# R7FA6M3AH register map
Vendor: Renesas; Series: RA6; File version: 1.2
CPU: CM4 r0p1, little endian, MPU, FPU, VTOR, 4 interrupt priority bits
Registers are 32-bit, read-write, reset 0x0 unless marked. A register's access mark holds for its fields unless they carry their own. Offsets are from the block's base; [hi:lo] are bit positions; {n}, {i} and the like mark numbered series; 'fields as' and 'values as' point back to an identical list.

## GLCDC — Graphics LCD Controller
Base 0x400E0000
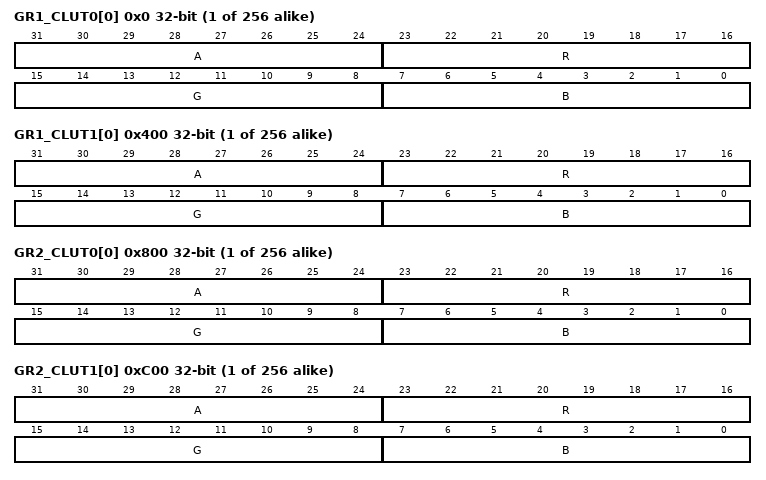
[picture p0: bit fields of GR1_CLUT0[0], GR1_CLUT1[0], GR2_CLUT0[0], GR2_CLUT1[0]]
{0x0+4i} GR1_CLUT0[{i}] (i=0..255) reset not defined — Color Palette 0 Plane for Graphics 1 Plane
  [31:24] A — Alpha Blending Value of Color Palette n Plane for Graphics m Plane
  [23:16] R — R Value of Color Palette n Plane for Graphics m Plane
  [15:8] G — G Value of Color Palette n Plane for Graphics m Plane
  [7:0] B — B Value of Color Palette n Plane for Graphics m Plane
{0x400+4i} GR1_CLUT1[{i}] (i=0..255) reset not defined — Color Palette 1 Plane for Graphics 1 Plane
  fields as GR1_CLUT0[0]
{0x800+4i} GR2_CLUT0[{i}] (i=0..255) reset not defined — Color Palette 0 Plane for Graphics 2 Plane
  fields as GR1_CLUT0[0]
{0xC00+4i} GR2_CLUT1[{i}] (i=0..255) reset not defined — Color Palette 1 Plane for Graphics 2 Plane
  fields as GR1_CLUT0[0]
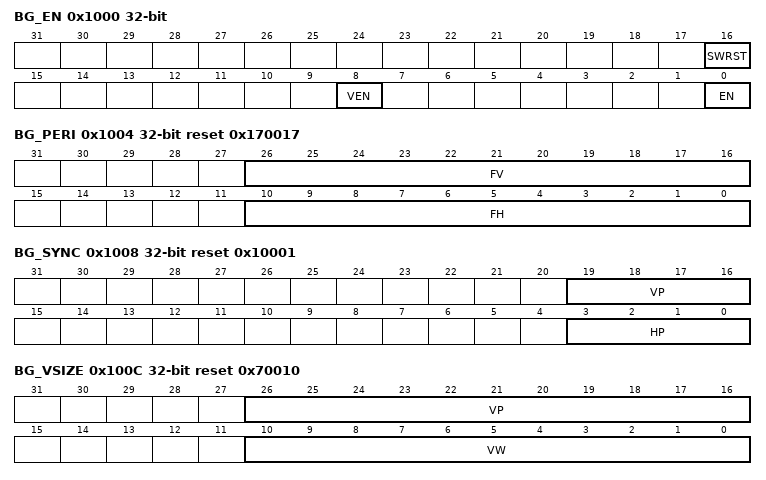
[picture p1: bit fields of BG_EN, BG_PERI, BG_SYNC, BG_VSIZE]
0x1000 BG_EN — Background Plane Setting Operation Control Register
  [16] SWRST — Entire module SW reset control
  [8] VEN write-1-sets read-modifies — Control of LCDC internal register value reflection to internal operations
  [0] EN — Background plane generation module operation enable
0x1004 BG_PERI reset 0x170017 — Background Plane Setting Free,Running Period Register
  [26:16] FV range 0x013..0x3FF — Background plane vertical synchronization signal period on the basis of line.
  [10:0] FH range 0x017..0x3FF — Background plane horizontal synchronization signal period on the basis of pixel clock (PXCLK).
0x1008 BG_SYNC reset 0x10001 — Background Plane Setting Synchronization Position Register
  [19:16] VP — Background plane vertical synchronization signal assertion position on the basis of line.
  [3:0] HP — Background plane horizontal synchronization signal assertion position on the basis of pixel clock (PXCLK).
0x100C BG_VSIZE reset 0x70010 — Background Plane Setting Full Image Vertical Size Register
  [26:16] VP range 0x0003..0x3EF — Background plane vertical valid pixel start position on the basis of line
  [10:0] VW range 0x0010..0x03FC — Background plane vertical valid pixel width on the basis of line
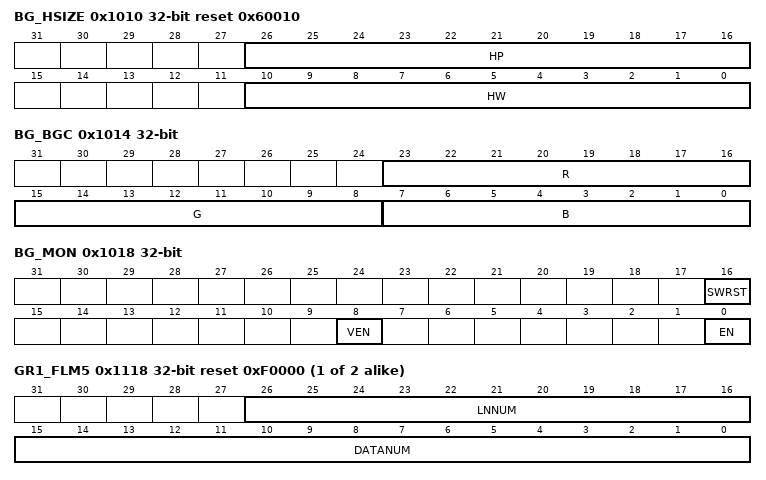
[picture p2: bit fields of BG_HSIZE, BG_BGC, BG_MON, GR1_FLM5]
0x1010 BG_HSIZE reset 0x60010 — Background Plane Setting Full Image Horizontal Size Register
  [26:16] HP range 0x006..0x3EE — Background plane horizontal valid pixel start position on the basis of pixel clock (PXCLK).
  [10:0] HW range 0x010..0x3F8 — Background plane horizontall valid pixel width on the basis of pixel clock (PXCLK)Note: When serial RGB is selected as the output format for the output control block, add two to the horizontal enable signal width and set the resulting value to this field.
0x1014 BG_BGC — Background Plane Setting Background Color Register
  [23:16] R — R value for background plane valid pixel area.Unsigned; 8-bit integer.
  [15:8] G — G value for background plane valid pixel areaUnsigned; 8-bit integer
  [7:0] B — B value for background plane valid pixel areaUnsigned; 8-bit integer
0x1018 BG_MON ro — Background Plane Setting Status Monitor Register
  [16] SWRST — Entire module SW reset state monitor.
  [8] VEN — Entire module internal operation reflection control signal monitor.The signal state for controlling reflection of the register values to the internal operations upon assertion of the vertical synchronization signal.
  [0] EN — Background plane generation module operation state monitor.
{0x1000+0x100*i} GR{i}_VEN (i=1..2) — Graphics {i} Register Update Control Register
  [0] PVEN write-0-clears read-modifies — Control of graphics n module register value reflection to internal operations.Reflection of the register values to the internal operation at the assertion of the vertical synchronization signal (VS).
{0x1004+0x100*i} GR{i}_FLMRD (i=1..2) — Graphics {i} Frame Buffer Read Control Register
  [0] RENB — Graphics data (frame buffer data) read enable.
{0x1008+0x100*i} GR{i}_FLM1 (i=1..2) reset 0x3 — Graphics {i} Frame Buffer Control Register 1
  [1:0] BSTMD — Burst transfer control for graphics data (frame buffer data)access
{0x100C+0x100*i} GR{i}_FLM2 (i=1..2) — Graphics {i} Frame Buffer Control Register 2
  [31:0] BASE — Base address for accessing graphics data (frame buffer data)Set the head address in the frame buffer where graphics data is to be stored. GRn_FLM2.BASE[5:0] should be fixed to 0 during 64-byte burst transfer.
{0x1010+0x100*i} GR{i}_FLM3 (i=1..2) — Graphics {i} Frame Buffer Control Register 3
  [31:16] LNOFF — Macro line offset address for accessing graphics data(frame buffer data)Signed; 16-bit integer
{0x1018+0x100*i} GR{i}_FLM5 (i=1..2) reset 0xF0000 — Graphics {i} Frame Buffer Control Register 5
  [26:16] LNNUM range 0x00F..0x3FF — Number of lines per frame for accessing graphics data (frame buffer data).
  [15:0] DATANUM — Number of data transfer times per line for accessing graphics data (frame buffer data), where one transfer is defined as 16-beat burst access (64-byte boundary)
{0x101C+0x100*i} GR{i}_FLM6 (i=1..2) — Graphics {i} Frame Buffer Control Register 6
  [30:28] FORMAT — Data format for accessing graphics data (frame buffer data).
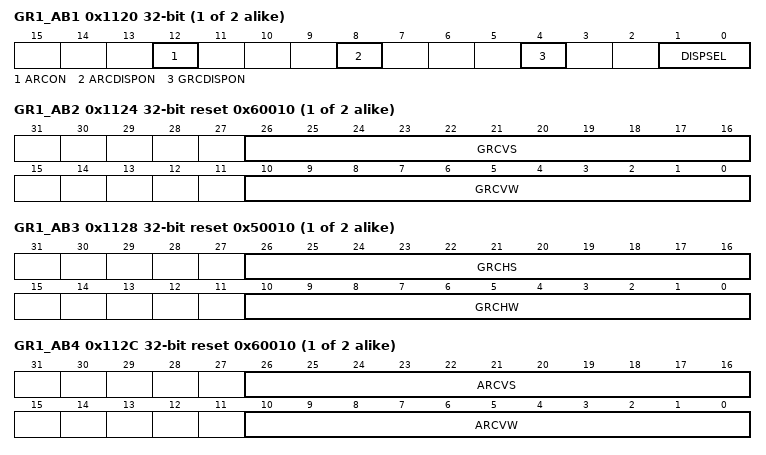
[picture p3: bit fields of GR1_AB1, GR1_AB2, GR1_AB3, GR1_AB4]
{0x1020+0x100*i} GR{i}_AB1 (i=1..2) — Graphics {i} Alpha Blending Control Register 1
  [12] ARCON — Rectangular area alpha blending control.
  [8] ARCDISPON — Image area border display control for rectangular area alpha blending.
  [4] GRCDISPON — Graphics image area border display control.
  [1:0] DISPSEL — Graphics display plane control.
{0x1024+0x100*i} GR{i}_AB2 (i=1..2) reset 0x60010 — Graphics {i} Alpha Blending Control Register 2
  [26:16] GRCVS range 0x002..0x3EE — Vertical start position of graphics image area.
  [10:0] GRCVW range 0x010..0x3FC — Vertical width of graphics image area.
{0x1028+0x100*i} GR{i}_AB3 (i=1..2) reset 0x50010 — Graphics {i} Alpha Blending Control Register 3
  [26:16] GRCHS range 0x005..0x3ED — Horizontal start position of graphics image area.
  [10:0] GRCHW range 0x010..0x3F0 — Horizontal width of graphics image area.
{0x102C+0x100*i} GR{i}_AB4 (i=1..2) reset 0x60010 — Graphics {i} Alpha Blending Control Register 4
  [26:16] ARCVS range 0x002..0x3EE — Vertical start position of rectangular area alpha blending image area
  [10:0] ARCVW range 0x001..0x3FC — Vertical width of rectangular area alpha blending image area.
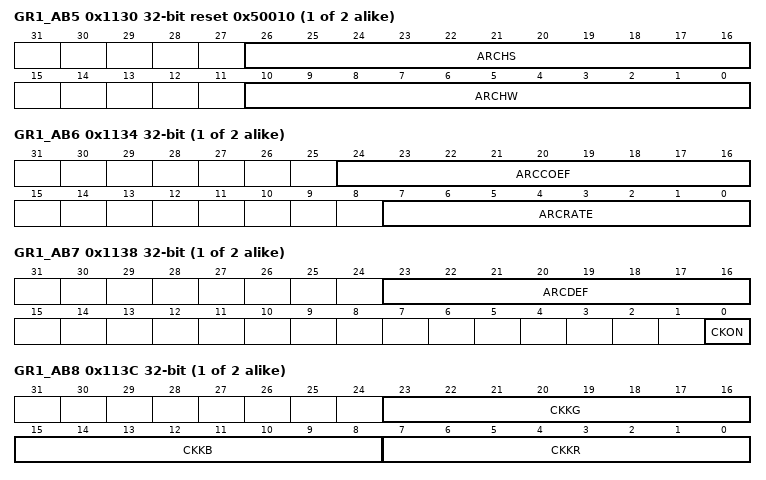
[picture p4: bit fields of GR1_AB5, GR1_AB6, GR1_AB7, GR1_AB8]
{0x1030+0x100*i} GR{i}_AB5 (i=1..2) reset 0x50010 — Graphics {i} Alpha Blending Control Register 5
  [26:16] ARCHS range 0x005..0x3ED — Horizontal start position of rectangular area alpha blending image area.
  [10:0] ARCHW range 0x001..0x3F8 — Horizontal width of rectangular area alpha blending image area.
{0x1034+0x100*i} GR{i}_AB6 (i=1..2) — Graphics {i} Alpha Blending Control Register 6
  [24:16] ARCCOEF — Alpha coefficient for alpha blending in rectangular area (-255 to 255).[8]: Sign (0: addition, 1: subtraction)[7:0]: Variation (absolute value)
  [7:0] ARCRATE — Frame rate for alpha blending in rectangular area.
{0x1038+0x100*i} GR{i}_AB7 (i=1..2) — Graphics {i} Alpha Blending Control Register 7
  [23:16] ARCDEF — Initial alpha value for alpha blending in rectangular area.
  [0] CKON — RGB,index chroma,key processing control.
{0x103C+0x100*i} GR{i}_AB8 (i=1..2) — Graphics {i} Alpha Blending Control Register 8
  [23:16] CKKG — G signal for RGB,index chroma,key processingUnsigned; 8 bits.
  [15:8] CKKB — B signal for RGB,index chroma,key processingUnsigned; 8 bits.
  [7:0] CKKR — R signal for RGB,index chroma,key processingUnsigned; 8 bits.
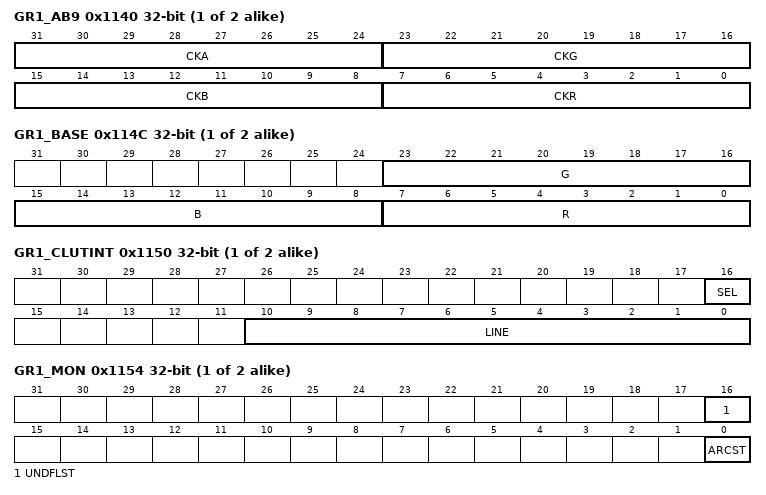
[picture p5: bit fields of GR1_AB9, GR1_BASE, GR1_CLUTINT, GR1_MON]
{0x1040+0x100*i} GR{i}_AB9 (i=1..2) — Graphics {i} Alpha Blending Control Register 9
  [31:24] CKA — A value after RGB,index chroma,key processing replacement.
  [23:16] CKG — G value after RGB,index chroma,key processing replacementUnsigned; 8 bits.
  [15:8] CKB — B value after RGB,index chroma,key processing replacementUnsigned; 8 bits.
  [7:0] CKR — R value after RGB,index chroma,key processing replacementUnsigned; 8 bits.
{0x104C+0x100*i} GR{i}_BASE (i=1..2) — Graphics {i} Background Color Control Register
  [23:16] G — Background color G valueUnsigned; 8 bits
  [15:8] B — Background color B valueUnsigned; 8 bits
  [7:0] R — Background color R valueUnsigned; 8 bits
{0x1050+0x100*i} GR{i}_CLUTINT (i=1..2) — Graphics {i} CLUT Table Interrupt Control Register
  [16] SEL — CLUT table control
  [10:0] LINE range 0x000..0x400 — Number of detection lines
{0x1054+0x100*i} GR{i}_MON (i=1..2) ro — Graphics {i} Status Monitor Register
  [16] UNDFLST — Status monitor for underflow
  [0] ARCST — Status monitor for alpha blending in rectangular area
0x1300 GAM{x}_LATCH (x=G,B,R; step 0x40) — Gamma {x} Register Update Control Register
  [0] VEN write-0-clears read-modifies — Control of gamma correction x module register value reflection to internal operations.The register values to be reflected to the internal operations at the assertion of the vertical synchronization signal (VS).
0x1304 GAM_SW — Gamma Correction Block Function Switch Register
  [0] GAMON — Gamma correction on/off control
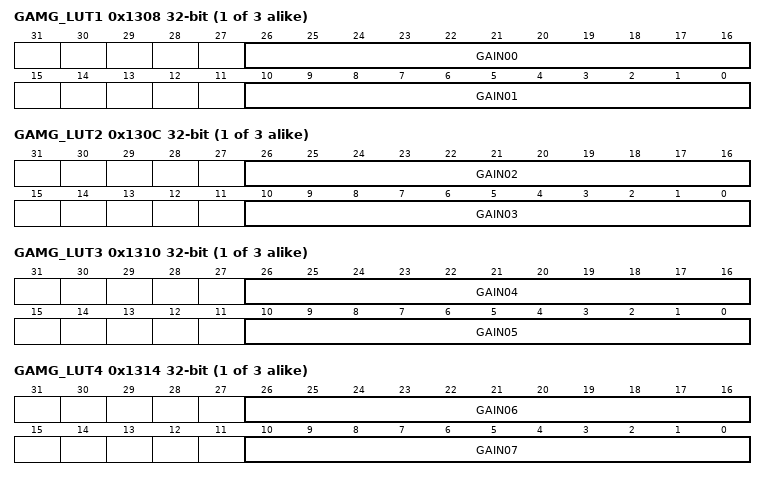
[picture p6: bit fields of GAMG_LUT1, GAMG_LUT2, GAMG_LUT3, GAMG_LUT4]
0x1308 GAM{x}_LUT1 (x=G,B,R; step 0x40) — Gamma {x} Correction Block Table Setting Register 1
  [26:16] GAIN00 — Gain value of area 0.Unsigned 11-bit fixed point.
  [10:0] GAIN01 — Gain value of area 1Unsigned 11-bit fixed point
0x130C GAM{x}_LUT2 (x=G,B,R; step 0x40) — Gamma {x} Correction Block Table Setting Register 2
  [26:16] GAIN02 — Gain value of area 2Unsigned 11-bit fixed point
  [10:0] GAIN03 — Gain value of area 3Unsigned 11-bit fixed point
0x1310 GAM{x}_LUT3 (x=G,B,R; step 0x40) — Gamma {x} Correction Block Table Setting Register 3
  [26:16] GAIN04 — Gain value of area 4Unsigned 11-bit fixed point
  [10:0] GAIN05 — Gain value of area 5Unsigned 11-bit fixed point
0x1314 GAM{x}_LUT4 (x=G,B,R; step 0x40) — Gamma {x} Correction Block Table Setting Register 4
  [26:16] GAIN06 — Gain value of area 6Unsigned 11-bit fixed point
  [10:0] GAIN07 — Gain value of area 7Unsigned 11-bit fixed point
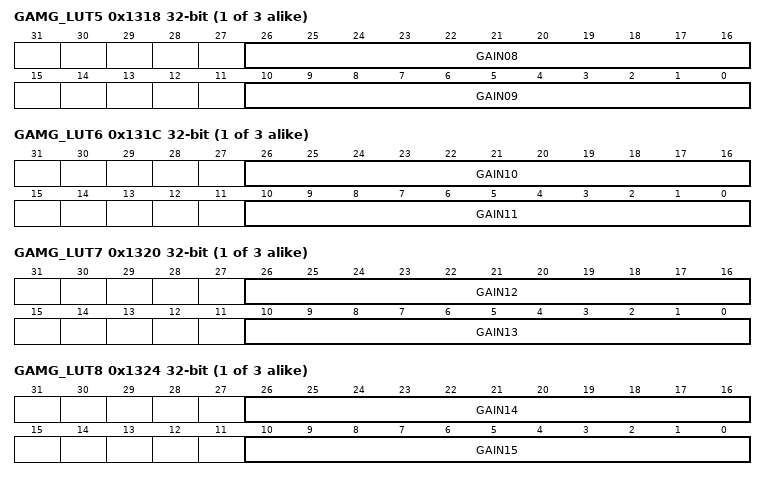
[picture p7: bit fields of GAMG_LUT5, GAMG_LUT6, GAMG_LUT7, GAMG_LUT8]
0x1318 GAM{x}_LUT5 (x=G,B,R; step 0x40) — Gamma {x} Correction Block Table Setting Register 5
  [26:16] GAIN08 — Gain value of area 8Unsigned 11-bit fixed point
  [10:0] GAIN09 — Gain value of area 9Unsigned 11-bit fixed point
0x131C GAM{x}_LUT6 (x=G,B,R; step 0x40) — Gamma {x} Correction Block Table Setting Register 6
  [26:16] GAIN10 — Gain value of area 10Unsigned 11-bit fixed point
  [10:0] GAIN11 — Gain value of area 11Unsigned 11-bit fixed point
0x1320 GAM{x}_LUT7 (x=G,B,R; step 0x40) — Gamma {x} Correction Block Table Setting Register 7
  [26:16] GAIN12 — Gain value of area 12Unsigned 11-bit fixed point
  [10:0] GAIN13 — Gain value of area 13Unsigned 11-bit fixed point
0x1324 GAM{x}_LUT8 (x=G,B,R; step 0x40) — Gamma {x} Correction Block Table Setting Register 8
  [26:16] GAIN14 — Gain value of area 14Unsigned 11-bit fixed point
  [10:0] GAIN15 — Gain value of area 15Unsigned 11-bit fixed point
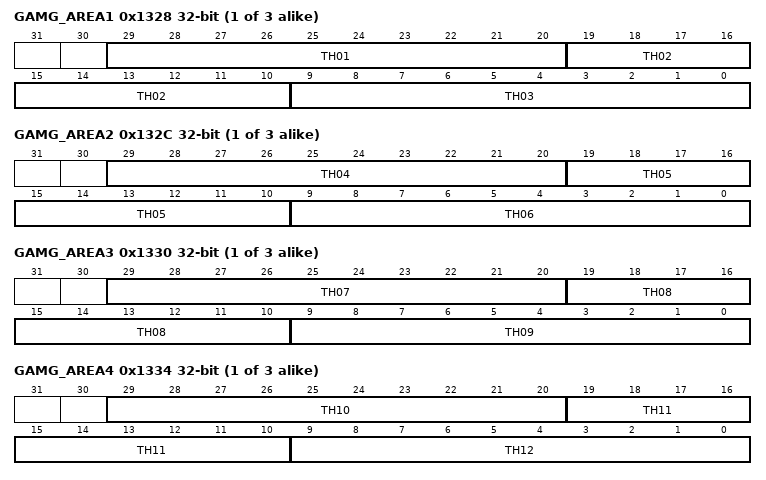
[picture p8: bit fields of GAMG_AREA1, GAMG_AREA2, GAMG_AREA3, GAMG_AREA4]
0x1328 GAM{x}_AREA1 (x=G,B,R; step 0x40) — Gamma {x} Correction Block Area Setting Register 1
  [29:20] TH01 — Start threshold of area 1Unsigned 10-bit integer
  [19:10] TH02 — Start threshold of area 2Unsigned 10-bit integer
  [9:0] TH03 — Start threshold of area 3Unsigned 10-bit integer
0x132C GAM{x}_AREA2 (x=G,B,R; step 0x40) — Gamma {x} Correction Block Area Setting Register 2
  [29:20] TH04 — Start threshold of area 4Unsigned 10-bit integer
  [19:10] TH05 — Start threshold of area 5Unsigned 10-bit integer
  [9:0] TH06 — Start threshold of area 6Unsigned 10-bit integer
0x1330 GAM{x}_AREA3 (x=G,B,R; step 0x40) — Gamma {x} Correction Block Area Setting Register 3
  [29:20] TH07 — Start threshold of area 7Unsigned 10-bit integer
  [19:10] TH08 — Start threshold of area 8Unsigned 10-bit integer
  [9:0] TH09 — Start threshold of area 9Unsigned 10-bit integer
0x1334 GAM{x}_AREA4 (x=G,B,R; step 0x40) — Gamma {x} Correction Block Area Setting Register 4
  [29:20] TH10 — Start threshold of area 10Unsigned 10-bit integer
  [19:10] TH11 — Start threshold of area 11Unsigned 10-bit integer
  [9:0] TH12 — Start threshold of area 12Unsigned 10-bit integer
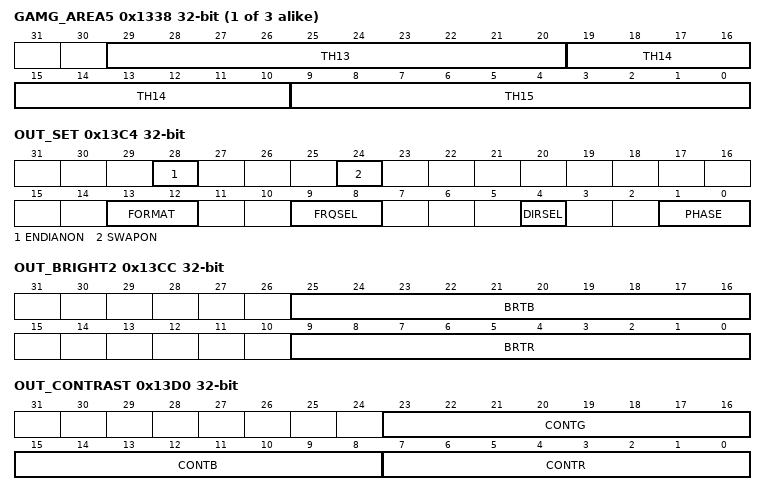
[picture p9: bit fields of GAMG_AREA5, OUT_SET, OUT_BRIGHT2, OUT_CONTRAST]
0x1338 GAM{x}_AREA5 (x=G,B,R; step 0x40) — Gamma {x} Correction Block Area Setting Register 5
  [29:20] TH13 — Start threshold of area 13Unsigned 10-bit integer
  [19:10] TH14 — Start threshold of area 14Unsigned 10-bit integer
  [9:0] TH15 — Start threshold of area 15Unsigned 10-bit integer
0x13C0 OUT_VLATCH — Output Control Block Register Update Control Register
  [0] VEN write-0-clears read-modifies — Control of output control module register value reflection to internal operations.The register values to be reflected to the internal operations at the assertion of the vertical synchronization signal (VS).
0x13C4 OUT_SET — Output Control Block Output Interface Register
  [28] ENDIANON — Bit endian change control
  [24] SWAPON — Pixel order control
  [13:12] FORMAT — Output format select
  [9:8] FRQSEL — Clock frequency division control
  [4] DIRSEL — Invalid data position control in serial RGB format
  [1:0] PHASE — Data delay in serial RGB format (based on OUTCLK)
0x13C8 OUT_BRIGHT1 — Output Control Block Brightness Correction Register 1
  [9:0] BRTG — Brightness (DC) adjustment of G signalUnsigned; 10 bits; +512 with offset; integer
0x13CC OUT_BRIGHT2 — Output Control Block Brightness Correction Register 2
  [25:16] BRTB — Brightness (DC) adjustment of B signalUnsigned; 10 bits; +512 with offset; integer
  [9:0] BRTR — Brightness (DC) adjustment of R signalUnsigned; 10 bits; +512 with offset; integer
0x13D0 OUT_CONTRAST — Output Control Block Contrast Correction Register
  [23:16] CONTG — Contrast (GAIN) adjustment of G signalUnsigned; 8 bits fixed point.
  [15:8] CONTB — Contrast (GAIN) adjustment of B signalUnsigned; 8 bits fixed point
  [7:0] CONTR — Contrast (GAIN) adjustment of R signalUnsigned; 8 bits fixed point
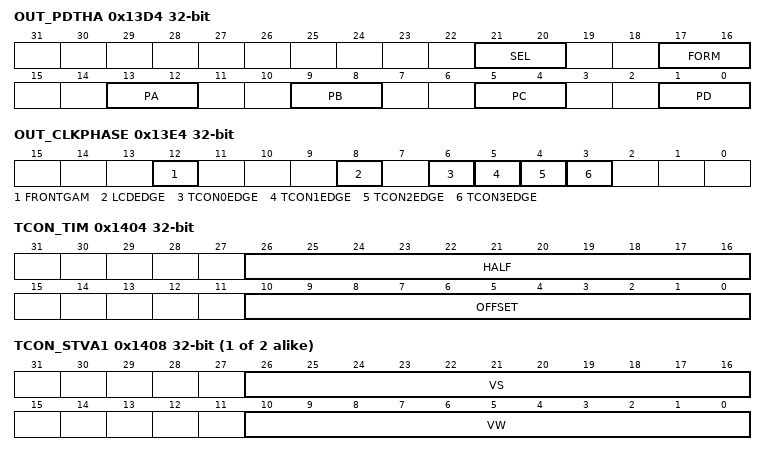
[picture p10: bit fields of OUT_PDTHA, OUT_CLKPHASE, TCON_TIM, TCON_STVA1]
0x13D4 OUT_PDTHA — Output Control Block Panel Dither Correction Register
  [21:20] SEL — Operation mode
  [17:16] FORM — Output format select
  [13:12] PA — Pattern value (A) of 2 x 2 pattern ditherUnsigned 2-bit integer
  [9:8] PB — Pattern value (B) of 2 x 2 pattern ditherUnsigned 2-bit integer
  [5:4] PC — Pattern value (C) of 2 x 2 pattern ditherUnsigned 2-bit integer
  [1:0] PD — Pattern value (D) of 2 x 2 pattern ditherUnsigned 2-bit integer
0x13E4 OUT_CLKPHASE — Output Control Block Output Phase Control Register
  [12] FRONTGAM — Correction control
  [8] LCDEDGE — LCD_DATA Output Phase Control
  [6-n] TCON{n}EDGE (n=0..3) — LCD_TCON{n} Output Phase Control
0x1404 TCON_TIM — TCON Reference Timing Setting Register
  [26:16] HALF range 0x000..0x3FF — Vertical synchronization signal generation change timing Sets the delay from the assertion of the internal horizontal synchronization signal in terms of pixels.
  [10:0] OFFSET range 0x000..0x3FF — Horizontal synchronization signal generation reference timingSets the offset from the assertion of the internal horizontal synchronization signal in terms of pixels.
0x1408 TCON_STV{x}1 (x=A,B; step 0x8) — TCON Vertical Timing Setting Register {x}1
  [26:16] VS range 0x000..0x7FF — STVx1 first change timing
  [10:0] VW range 0x000..0x7FF — STVx1 second change timingSets the signal assertion width.
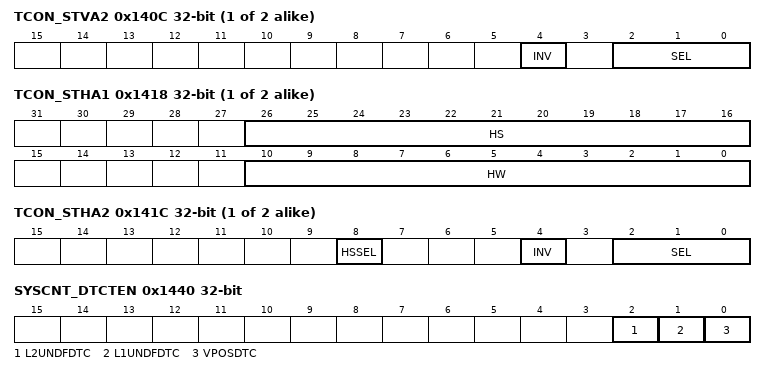
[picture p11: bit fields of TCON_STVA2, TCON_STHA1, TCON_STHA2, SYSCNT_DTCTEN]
0x140C TCON_STV{x}2 (x=A,B; step 0x8) — TCON Vertical Timing Setting Register {x}2
  [4] INV — STVx signal polarity inversion control
  [2:0] SEL — Output signal select control for VSOUT (controlled by TCON_STVA2 register)/VEOUT (controlled by the TCON_STVB2 register) pin
0x1418 TCON_STH{x}1 (x=A,B; step 0x8) — TCON Horizontal Timing Setting Register STH{x}1
  [26:16] HS range 0x000..0x3FF — STHx1 first change timing
  [10:0] HW range 0x000..0x3FF — STHx1 second change timing.Sets the signal assertion width.
0x141C TCON_STH{x}2 (x=A,B; step 0x8) — TCON Horizontal Timing Setting Register STH{x}2
  [8] HSSEL — STHx signal generation reference timing control.
  [4] INV — STVx signal polarity inversion control.
  [2:0] SEL — Output signal select control for LCD_TCON2 (controlled by TCON_STHA2 register)/LCD_TCON3 (controlled by the TCON_STHB2 register) pin.
0x1428 TCON_DE — TCON Data Enable Polarity Setting Register
  [0] INV — DE signal polarity inversion control.
0x1440 SYSCNT_DTCTEN — System Control Block State Detection Control Register
  [2] L2UNDFDTC — Graphics 2 underflow detection control
  [1] L1UNDFDTC — Graphics 1 underflow detection control
  [0] VPOSDTC — Specified line detection control
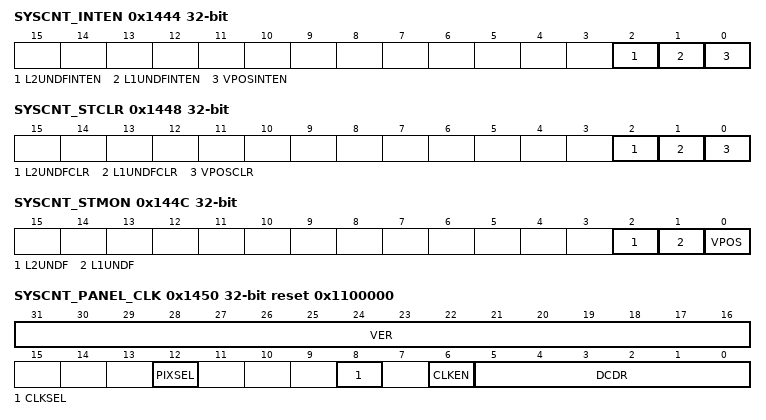
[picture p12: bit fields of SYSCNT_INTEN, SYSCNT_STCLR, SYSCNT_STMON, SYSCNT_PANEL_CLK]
0x1444 SYSCNT_INTEN — System Control Block Interrupt Request Enable Control Register
  [2] L2UNDFINTEN — Interrupt request signal GLCDC_L2UNDF enable control.
  [1] L1UNDFINTEN — Interrupt request signal GLCDC_L1UNDF enable control.
  [0] VPOSINTEN — Interrupt request signal GLCDC_VPOS enable control.
0x1448 SYSCNT_STCLR — System Control Block Status Clear Register
  [2] L2UNDFCLR — Graphics 2 underflow detection flag clear field
  [1] L1UNDFCLR — Graphics 1 underflow detection flag clear field
  [0] VPOSCLR — Graphics 2 specified line detection flag clear field
0x144C SYSCNT_STMON ro — System Control Block Status Monitor Register
  [2] L2UNDF — Graphics 2 underflow detection flag
  [1] L1UNDF — Graphics 1 underflow detection flag
  [0] VPOS — Graphics 2 specified line detection flag
0x1450 SYSCNT_PANEL_CLK reset 0x1100000 — System Control Block Version and Panel Clock Control Register
  [31:16] VER ro — Version informationVersion information of the GLCD
  [12] PIXSEL — Pixel clock select control.Must be set to the same value as OUT_SET.FRQSEL[1].
  [8] CLKSEL — Panel clock supply source select
  [6] CLKEN — Panel clock output enable controlNote: Before changing the PIXSEL,CLKSEL or DCDR bit, this bit must be set to 0.
  [5:0] DCDR — Clock division ratio setting controlRefer toTable 2.7.1 for details about setting value.Note: Settings that are not listed in table 2.7.1 are prohibited.
